# EFR32FG1V131F256GM48 register map
File version: 3.0.0
CPU: CM4 r0p1, little endian, MPU, FPU, 3 interrupt priority bits
Registers are 32-bit, read-write, reset 0x0 unless marked. A register's access mark holds for its fields unless they carry their own. Offsets are from the block's base; [hi:lo] are bit positions; {n}, {i} and the like mark numbered series; 'fields as' and 'values as' point back to an identical list.

## FRC — Frame controller
Base 0x40080000
Same registers: FRC_CLR 0x44080000, FRC_SET 0x46080000
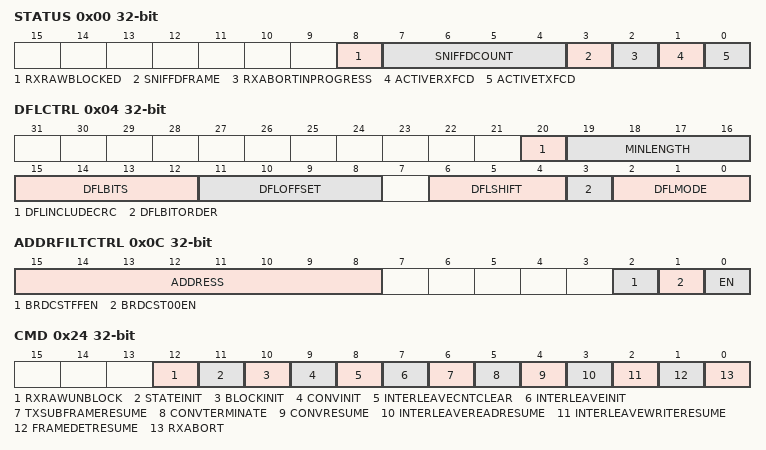
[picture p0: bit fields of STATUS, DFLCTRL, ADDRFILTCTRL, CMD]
0x00 STATUS ro
  [8] RXRAWBLOCKED, [7:4] SNIFFDCOUNT, [3] SNIFFDFRAME, [2] RXABORTINPROGRESS, [1] ACTIVERXFCD, [0] ACTIVETXFCD
0x04 DFLCTRL
  [20] DFLINCLUDECRC, [19:16] MINLENGTH, [15:12] DFLBITS, [11:8] DFLOFFSET, [6:4] DFLSHIFT, [3] DFLBITORDER, [2:0] DFLMODE
0x08 MAXLENGTH reset 0xFFF
  [11:0] MAXLENGTH
0x0C ADDRFILTCTRL
  [15:8] ADDRESS, [2] BRDCSTFFEN, [1] BRDCST00EN, [0] EN
0x10 DATABUFFER
  [7:0] DATABUFFER
0x14 WCNT
  [11:0] WCNT
0x18 WCNTCMP0
  [11:0] FRAMELENGTH
0x1C WCNTCMP1
  [11:0] LENGTHFIELDLOC
0x20 WCNTCMP2
  [11:0] ADDRFIELDLOC
0x24 CMD wo
  [12] RXRAWUNBLOCK, [11] STATEINIT, [10] BLOCKINIT, [9] CONVINIT, [8] INTERLEAVECNTCLEAR, [7] INTERLEAVEINIT, [6] TXSUBFRAMERESUME, [5] CONVTERMINATE, [4] CONVRESUME, [3] INTERLEAVEREADRESUME, [2] INTERLEAVEWRITERESUME, [1] FRAMEDETRESUME, [0] RXABORT
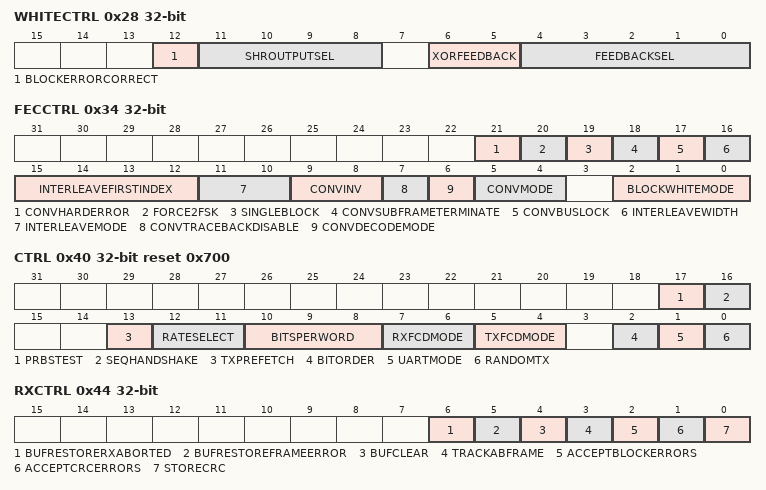
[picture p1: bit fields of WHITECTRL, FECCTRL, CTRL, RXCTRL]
0x28 WHITECTRL
  [12] BLOCKERRORCORRECT, [11:8] SHROUTPUTSEL, [6:5] XORFEEDBACK, [4:0] FEEDBACKSEL
0x2C WHITEPOLY
  [15:0] POLY
0x30 WHITEINIT
  [15:0] WHITEINIT
0x34 FECCTRL
  [21] CONVHARDERROR, [20] FORCE2FSK, [19] SINGLEBLOCK, [18] CONVSUBFRAMETERMINATE, [17] CONVBUSLOCK, [16] INTERLEAVEWIDTH, [15:12] INTERLEAVEFIRSTINDEX, [11:10] INTERLEAVEMODE, [9:8] CONVINV, [7] CONVTRACEBACKDISABLE, [6] CONVDECODEMODE, [5:4] CONVMODE, [2:0] BLOCKWHITEMODE
0x38 BLOCKRAMADDR
  [14:2] BLOCKRAMADDR
0x3C CONVRAMADDR
  [14:2] CONVRAMADDR
0x40 CTRL reset 0x700
  [17] PRBSTEST, [16] SEQHANDSHAKE, [13] TXPREFETCH, [12:11] RATESELECT, [10:8] BITSPERWORD, [7:6] RXFCDMODE, [5:4] TXFCDMODE, [2] BITORDER, [1] UARTMODE, [0] RANDOMTX
0x44 RXCTRL
  [6] BUFRESTORERXABORTED, [5] BUFRESTOREFRAMEERROR, [4] BUFCLEAR, [3] TRACKABFRAME, [2] ACCEPTBLOCKERRORS, [1] ACCEPTCRCERRORS, [0] STORECRC
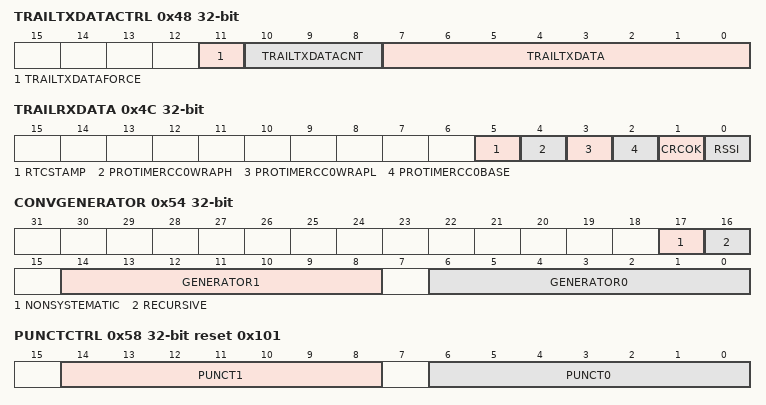
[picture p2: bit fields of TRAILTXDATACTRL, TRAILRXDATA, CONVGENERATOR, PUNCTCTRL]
0x48 TRAILTXDATACTRL
  [11] TRAILTXDATAFORCE, [10:8] TRAILTXDATACNT, [7:0] TRAILTXDATA
0x4C TRAILRXDATA
  [5] RTCSTAMP, [4] PROTIMERCC0WRAPH, [3] PROTIMERCC0WRAPL, [2] PROTIMERCC0BASE, [1] CRCOK, [0] RSSI
0x50 SCNT ro
  [7:0] SCNT
0x54 CONVGENERATOR
  [17] NONSYSTEMATIC, [16] RECURSIVE, [14:8] GENERATOR1, [6:0] GENERATOR0
0x58 PUNCTCTRL reset 0x101
  [14:8] PUNCT1, [6:0] PUNCT0
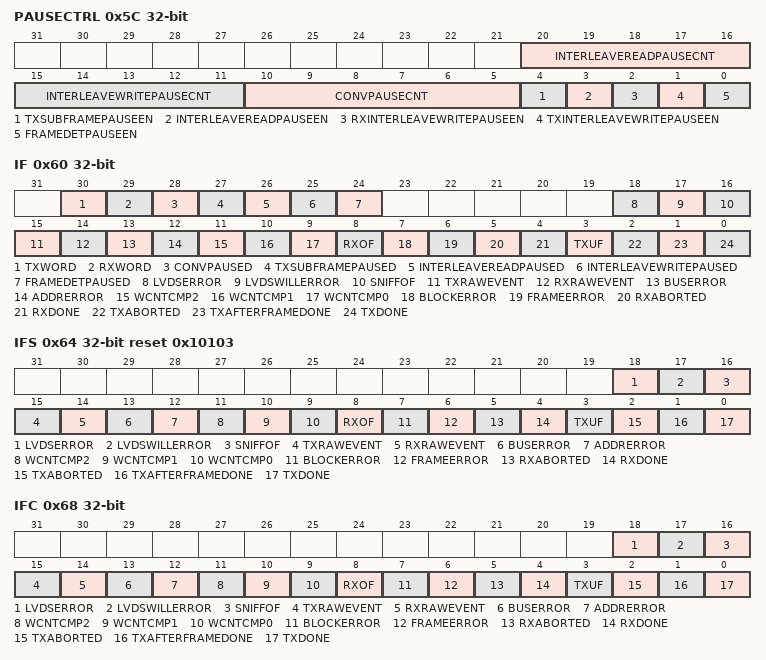
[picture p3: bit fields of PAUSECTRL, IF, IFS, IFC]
0x5C PAUSECTRL
  [20:16] INTERLEAVEREADPAUSECNT, [15:11] INTERLEAVEWRITEPAUSECNT, [10:5] CONVPAUSECNT, [4] TXSUBFRAMEPAUSEEN, [3] INTERLEAVEREADPAUSEEN, [2] RXINTERLEAVEWRITEPAUSEEN, [1] TXINTERLEAVEWRITEPAUSEEN, [0] FRAMEDETPAUSEEN
0x60 IF ro
  [30] TXWORD, [29] RXWORD, [28] CONVPAUSED, [27] TXSUBFRAMEPAUSED, [26] INTERLEAVEREADPAUSED, [25] INTERLEAVEWRITEPAUSED, [24] FRAMEDETPAUSED, [18] LVDSERROR, [17] LVDSWILLERROR, [16] SNIFFOF, [15] TXRAWEVENT, [14] RXRAWEVENT, [13] BUSERROR, [12] ADDRERROR, [11] WCNTCMP2, [10] WCNTCMP1, [9] WCNTCMP0, [8] RXOF, [7] BLOCKERROR, [6] FRAMEERROR, [5] RXABORTED, [4] RXDONE, [3] TXUF, [2] TXABORTED, [1] TXAFTERFRAMEDONE, [0] TXDONE
0x64 IFS wo reset 0x10103
  [18] LVDSERROR, [17] LVDSWILLERROR, [16] SNIFFOF, [15] TXRAWEVENT, [14] RXRAWEVENT, [13] BUSERROR, [12] ADDRERROR, [11] WCNTCMP2, [10] WCNTCMP1, [9] WCNTCMP0, [8] RXOF, [7] BLOCKERROR, [6] FRAMEERROR, [5] RXABORTED, [4] RXDONE, [3] TXUF, [2] TXABORTED, [1] TXAFTERFRAMEDONE, [0] TXDONE
0x68 IFC wo
  fields as IFS
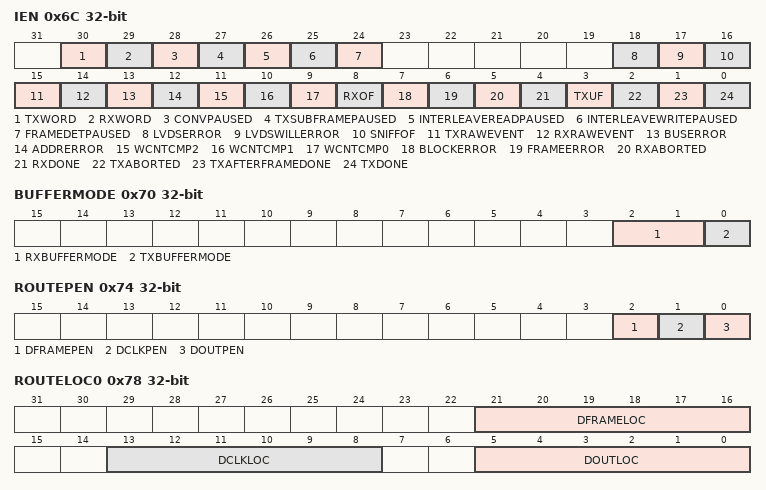
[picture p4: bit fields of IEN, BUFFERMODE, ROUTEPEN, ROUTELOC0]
0x6C IEN
  fields as IF
0x70 BUFFERMODE
  [2:1] RXBUFFERMODE, [0] TXBUFFERMODE
0x74 ROUTEPEN
  [2] DFRAMEPEN, [1] DCLKPEN, [0] DOUTPEN
0x78 ROUTELOC0
  [21:16] DFRAMELOC, [13:8] DCLKLOC, [5:0] DOUTLOC
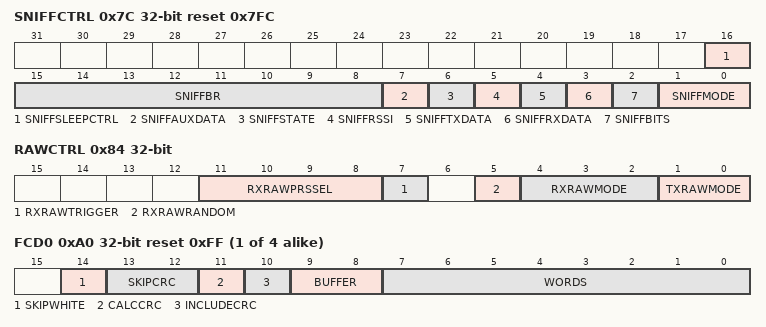
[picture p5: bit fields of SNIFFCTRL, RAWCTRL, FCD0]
0x7C SNIFFCTRL reset 0x7FC
  [16] SNIFFSLEEPCTRL, [15:8] SNIFFBR, [7] SNIFFAUXDATA, [6] SNIFFSTATE, [5] SNIFFRSSI, [4] SNIFFTXDATA, [3] SNIFFRXDATA, [2] SNIFFBITS, [1:0] SNIFFMODE
0x80 AUXDATA
  [8:0] AUXDATA
0x84 RAWCTRL
  [11:8] RXRAWPRSSEL, [7] RXRAWTRIGGER, [5] RXRAWRANDOM, [4:2] RXRAWMODE, [1:0] TXRAWMODE
0x88 RXRAWDATA ro
0x8C PAUSEDATA ro
  [5:0] PAUSEDATA
0x90 LIKELYCONVSTATE ro
  [5:0] LIKELYCONVSTATE
0x94 INTELEMENTNEXT ro
  [7:0] INTELEMENTNEXT
0x98 INTWRITEPOINT
  [4:0] INTWRITEPOINT
0x9C INTREADPOINT
  [4:0] INTREADPOINT
{0xA0+4i} FCD{i} reset 0xFF (i=0..3)
  [14] SKIPWHITE, [13:12] SKIPCRC, [11] CALCCRC, [10] INCLUDECRC, [9:8] BUFFER, [7:0] WORDS
{0xC0+4i} INTELEMENT{i} ro (i=0..9)
  [7:0] INTELEMENT
0xE8 INTELEMENT10 ro
  [7:0] INTELEMENTN
{0xC0+4i} INTELEMENT{i} ro (i=11..15)
  [7:0] INTELEMENT
